# WBZ451 register map
Vendor: Microchip
Registers are 32-bit, read-write, reset 0x0 unless marked. A register's access mark holds for its fields unless they carry their own. Addresses are absolute, and some are shared; only a register's first bit layout is shown; [hi:lo] are bit positions; {n}, {i} and the like mark numbered series; 'fields as' and 'values as' point back to an identical list.

## PAC
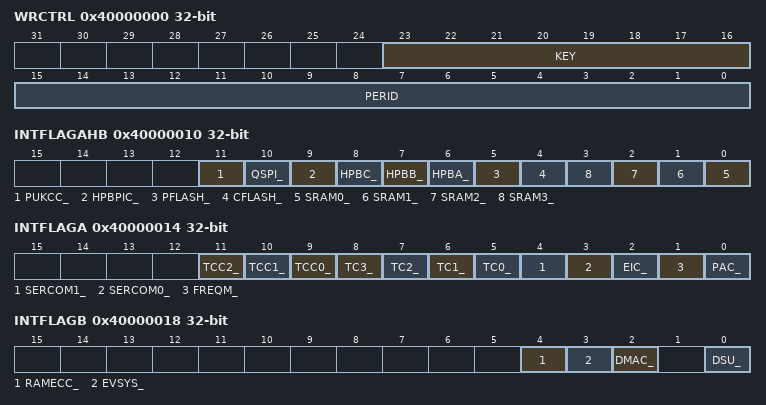
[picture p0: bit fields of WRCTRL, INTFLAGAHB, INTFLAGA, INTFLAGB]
0x40000000 WRCTRL
  [23:16] KEY — Peripheral access control key
    0=OFF (No action); 1=CLR (Clear protection); 2=SET (Set protection); 3=SETLCK (Set and lock protection)
  [15:0] PERID — Peripheral identifier
0x40000004 EVCTRL 8-bit
  [0] ERREO — Peripheral acess error event output
0x40000008 INTENCLR 8-bit
  [0] ERR — Peripheral access error interrupt disable
0x40000009 INTENSET 8-bit
  [0] ERR — Peripheral access error interrupt enable
0x40000010 INTFLAGAHB
  [11] PUKCC_
  [10] QSPI_
  [9] HPBPIC_ — HPBPIC0
  [8] HPBC_
  [7] HPBB_
  [6] HPBA_
  [5] PFLASH_
  [4] CFLASH_
  [n] SRAM{n}_ (n=0..3)
0x40000014 INTFLAGA
  [11] TCC2_, [10] TCC1_, [9] TCC0_, [n+5] TC{n}_ (n=0..3), [4] SERCOM1_, [3] SERCOM0_, [2] EIC_, [1] FREQM_, [0] PAC_
0x40000018 INTFLAGB
  [4] RAMECC_, [3] EVSYS_, [2] DMAC_, [0] DSU_
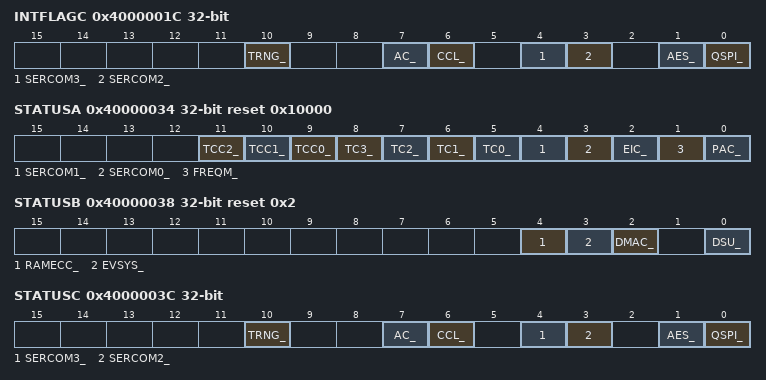
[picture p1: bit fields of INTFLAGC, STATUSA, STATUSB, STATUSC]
0x4000001C INTFLAGC
  [10] TRNG_, [7] AC_, [6] CCL_, [4] SERCOM3_, [3] SERCOM2_, [1] AES_, [0] QSPI_
0x40000034 STATUSA ro reset 0x10000
  [11] TCC2_ — TCC2 APB Protect Enable
  [10] TCC1_ — TCC1 APB Protect Enable
  [9] TCC0_ — TCC0 APB Protect Enable
  [n+5] TC{n}_ (n=0..3) — TC{n} APB Protect Enable
  [4] SERCOM1_ — SERCOM1 APB Protect Enable
  [3] SERCOM0_ — SERCOM0 APB Protect Enable
  [2] EIC_ — EIC APB Protect Enable
  [1] FREQM_ — FREQM APB Protect Enable
  [0] PAC_ — PAC APB Protect Enable
0x40000038 STATUSB ro reset 0x2
  [4] RAMECC_ — RAMECC APB Protect Enable
  [3] EVSYS_ — EVSYS APB Protect Enable
  [2] DMAC_ — DMAC APB Protect Enable
  [0] DSU_ — DSU APB Protect Enable
0x4000003C STATUSC ro
  [10] TRNG_ — TRNG APB Protect Enable
  [7] AC_ — AC APB Protect Enable
  [6] CCL_ — CCL APB Protect Enable
  [4] SERCOM3_ — SERCOM3 APB Protect Enable
  [3] SERCOM2_ — SERCOM2 APB Protect Enable
  [1] AES_ — AES APB Protect Enable
  [0] QSPI_ — QSPI APB Protect Enable

## FREQM
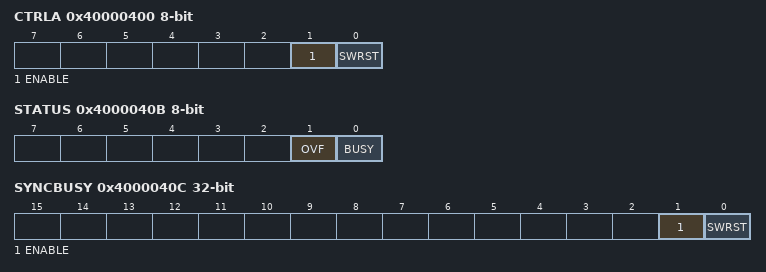
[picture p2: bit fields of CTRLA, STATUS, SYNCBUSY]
0x40000400 CTRLA 8-bit
  [1] ENABLE
  [0] SWRST — Software Reset
0x40000401 CTRLB 8-bit wo
  [0] START — Start Measurement
0x40000402 CFGA 16-bit
  [7:0] REFNUM — Number of Reference Clock Cycles
0x40000408 INTENCLR 8-bit
  [0] DONE — Measurement Done Interrupt Enable
0x40000409 INTENSET 8-bit
  [0] DONE — Measurement Done Interrupt Enable
0x4000040A INTFLAG 8-bit
  [0] DONE — Measurement Done
0x4000040B STATUS 8-bit
  [1] OVF — Sticky Count Value Overflow
  [0] BUSY — FREQM Status
0x4000040C SYNCBUSY ro
  [1] ENABLE
  [0] SWRST — Software Reset
0x40000410 VALUE ro
  [23:0] VALUE — Measurement Value

## EIC
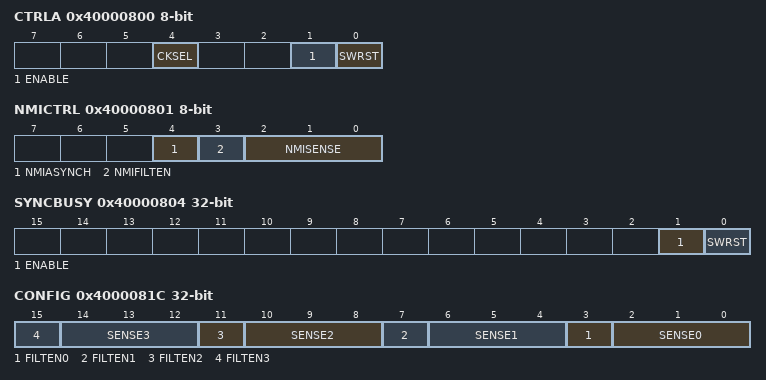
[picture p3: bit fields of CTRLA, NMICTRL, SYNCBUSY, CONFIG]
0x40000800 CTRLA 8-bit
  [4] CKSEL — Clock Selection
    0=CLK_GCLK (Clocked by GCLK); 1=CLK_ULP32K (Clocked by ULP32K)
  [1] ENABLE
  [0] SWRST — Software Reset
0x40000801 NMICTRL 8-bit
  [4] NMIASYNCH — Asynchronous Edge Detection Mode
    0=SYNC (Edge detection is clock synchronously operated); 1=ASYNC (Edge detection is clock asynchronously operated)
  [3] NMIFILTEN — Non-Maskable Interrupt Filter Enable
  [2:0] NMISENSE — Non-Maskable Interrupt Sense Configuration
    0=NONE (No detection); 1=RISE (Rising-edge detection); 2=FALL (Falling-edge detection); 3=BOTH (Both-edges detection); 4=HIGH (High-level detection); 5=LOW (Low-level detection)
0x40000802 NMIFLAG 16-bit
  [0] NMI — Non-Maskable Interrupt
0x40000804 SYNCBUSY ro
  [1] ENABLE — Enable Synchronization Busy Status
  [0] SWRST — Software Reset Synchronization Busy Status
0x40000808 EVCTRL
  [3:0] EXTINTEO — External Interrupt Event Output Enable
0x4000080C INTENCLR
  [3:0] EXTINT — External Interrupt Enable
0x40000810 INTENSET
  [3:0] EXTINT — External Interrupt Enable
0x40000814 INTFLAG
  [3:0] EXTINT — External Interrupt
0x40000818 ASYNCH
  [3:0] ASYNCH — Asynchronous Edge Detection Mode
    values as NMICTRL.NMIASYNCH
0x4000081C CONFIG
  [4n+3] FILTEN{n} (n=0..3) — Filter Enable {n}
  [4n+2:4n] SENSE{n} (n=0..3) — Input Sense Configuration {n}
    0=NONE (No detection); 1=RISE (Rising edge detection); 2=FALL (Falling edge detection); 3=BOTH (Both edges detection); 4=HIGH (High level detection); 5=LOW (Low level detection)
0x40000830 DEBOUNCEN
  [3:0] DEBOUNCEN — Debouncer Enable
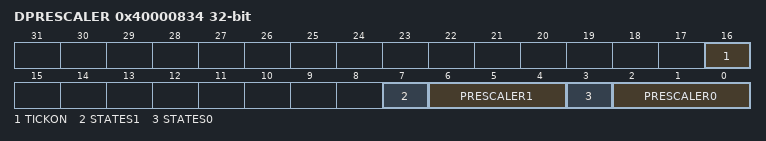
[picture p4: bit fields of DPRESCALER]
0x40000834 DPRESCALER
  [16] TICKON — Pin Sampler frequency selection
    0=CLK_GCLK_EIC (Clocked by GCLK); 1=CLK_LFREQ (Clocked by Low Frequency Clock)
  [7] STATES1 — Debouncer number of states
    0=LFREQ3 (3 low frequency samples); 1=LFREQ7 (7 low frequency samples)
  [6:4] PRESCALER1 — Debouncer Prescaler
    0=DIV2 (EIC clock divided by 2); 1=DIV4 (EIC clock divided by 4); 2=DIV8 (EIC clock divided by 8); 3=DIV16 (EIC clock divided by 16); 4=DIV32 (EIC clock divided by 32); 5=DIV64 (EIC clock divided by 64); 6=DIV128 (EIC clock divided by 128); 7=DIV256 (EIC clock divided by 256)
  [3] STATES0 — Debouncer number of states
    values as STATES1
  [2:0] PRESCALER0 — Debouncer Prescaler
    values as PRESCALER1
0x40000838 PINSTATE ro
  [3:0] PINSTATE
